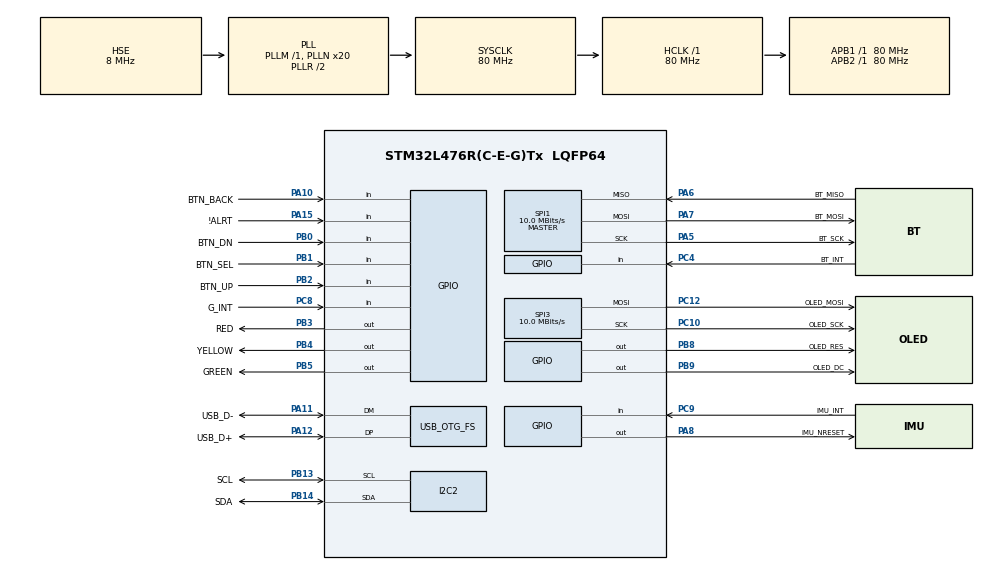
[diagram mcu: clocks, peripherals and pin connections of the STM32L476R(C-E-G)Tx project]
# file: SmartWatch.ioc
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Dma.Request0=SPI3_TX
Dma.Request1=SPI1_TX
Dma.Request2=SPI1_RX
Dma.SPI1_RX.2.Direction=DMA_PERIPH_TO_MEMORY
Dma.SPI1_RX.2.Instance=DMA1_Channel2
Dma.SPI1_RX.2.MemDataAlignment=DMA_MDATAALIGN_BYTE
Dma.SPI1_RX.2.MemInc=DMA_MINC_DISABLE
Dma.SPI1_RX.2.Mode=DMA_NORMAL
Dma.SPI1_RX.2.NoTestForDmaSupport=false
Dma.SPI1_RX.2.PeriphDataAlignment=DMA_PDATAALIGN_BYTE
Dma.SPI1_RX.2.PeriphInc=DMA_PINC_DISABLE
Dma.SPI1_RX.2.Priority=DMA_PRIORITY_LOW
Dma.SPI1_RX.2.Request=DMA_REQUEST_1
Dma.SPI1_TX.1.Direction=DMA_MEMORY_TO_PERIPH
Dma.SPI1_TX.1.Instance=DMA1_Channel3
Dma.SPI1_TX.1.MemDataAlignment=DMA_MDATAALIGN_BYTE
Dma.SPI1_TX.1.MemInc=DMA_MINC_DISABLE
Dma.SPI1_TX.1.Mode=DMA_NORMAL
Dma.SPI1_TX.1.NoTestForDmaSupport=false
Dma.SPI1_TX.1.PeriphDataAlignment=DMA_PDATAALIGN_BYTE
Dma.SPI1_TX.1.PeriphInc=DMA_PINC_DISABLE
Dma.SPI1_TX.1.Priority=DMA_PRIORITY_LOW
Dma.SPI1_TX.1.Request=DMA_REQUEST_1
Dma.SPI3_TX.0.Direction=DMA_MEMORY_TO_PERIPH
Dma.SPI3_TX.0.Instance=DMA2_Channel2
Dma.SPI3_TX.0.MemDataAlignment=DMA_MDATAALIGN_BYTE
Dma.SPI3_TX.0.MemInc=DMA_MINC_DISABLE
Dma.SPI3_TX.0.Mode=DMA_NORMAL
Dma.SPI3_TX.0.NoTestForDmaSupport=false
Dma.SPI3_TX.0.PeriphDataAlignment=DMA_PDATAALIGN_BYTE
Dma.SPI3_TX.0.PeriphInc=DMA_PINC_DISABLE
Dma.SPI3_TX.0.Priority=DMA_PRIORITY_LOW
Dma.SPI3_TX.0.Request=DMA_REQUEST_3
Mcu.Family=STM32L4
Mcu.Name=STM32L476R(C-E-G)Tx
Mcu.Package=LQFP64
NVIC.DMA1_Channel2_IRQn=true\:0\:0\:false
NVIC.DMA1_Channel3_IRQn=true\:0\:0\:false
NVIC.DMA2_Channel2_IRQn=true\:0\:0\:false
NVIC.PriorityGroup=NVIC_PRIORITYGROUP_4
PA10.GPIO_Label=BTN_BACK
PA10.Signal=GPIO_Input
PA11.GPIO_Label=USB_D-
PA11.Mode=Device_Only
PA11.Signal=USB_OTG_FS_DM
PA12.GPIO_Label=USB_D+
PA12.Mode=Device_Only
PA12.Signal=USB_OTG_FS_DP
PA13.GPIO_Label=SWDIO
PA13.Mode=Serial-Wire
PA13.Signal=SYS_JTMS-SWDIO
PA14.GPIO_Label=SWCLK
PA14.Mode=Serial-Wire
PA14.Signal=SYS_JTCK-SWCLK
PA15.GPIO_Label=\!ALRT
PA15.Signal=GPIO_Input
PA5.GPIO_Label=BT_SCK
PA5.Mode=Full_Duplex_Master
PA5.Signal=SPI1_SCK
PA6.GPIO_Label=BT_MISO
PA6.Mode=Full_Duplex_Master
PA6.Signal=SPI1_MISO
PA7.GPIO_Label=BT_MOSI
PA7.Mode=Full_Duplex_Master
PA7.Signal=SPI1_MOSI
PA8.GPIO_Label=IMU_NRESET
PA8.Signal=GPIO_Output
PB0.GPIO_Label=BTN_DN
PB0.Signal=GPIO_Input
PB1.GPIO_Label=BTN_SEL
PB1.Signal=GPIO_Input
PB13.GPIO_Label=SCL
PB13.Mode=I2C
PB13.Signal=I2C2_SCL
PB14.GPIO_Label=SDA
PB14.Mode=I2C
PB14.Signal=I2C2_SDA
PB2.GPIO_Label=BTN_UP
PB2.Signal=GPIO_Input
PB3.GPIO_Label=RED
PB3.GPIO_PuPd=GPIO_PULLDOWN
PB3.Signal=GPIO_Output
PB4.GPIO_Label=YELLOW
PB4.GPIO_ModeDefaultOutputPP=GPIO_MODE_OUTPUT_PP
PB4.GPIO_PuPd=GPIO_PULLDOWN
PB4.Signal=GPIO_Output
PB5.GPIO_Label=GREEN
PB5.GPIO_PuPd=GPIO_PULLDOWN
PB5.Signal=GPIO_Output
PB8.GPIO_Label=OLED_RES
PB8.GPIO_ModeDefaultOutputPP=GPIO_MODE_OUTPUT_PP
PB8.GPIO_PuPd=GPIO_NOPULL
PB8.Signal=GPIO_Output
PB9.GPIO_Label=OLED_DC
PB9.Signal=GPIO_Output
PC10.GPIO_Label=OLED_SCK
PC10.Mode=TX_Only_Simplex_Unidirect_Master
PC10.Signal=SPI3_SCK
PC12.GPIO_Label=OLED_MOSI
PC12.Mode=TX_Only_Simplex_Unidirect_Master
PC12.Signal=SPI3_MOSI
PC14/OSC32_IN.GPIO_Label=OSC32_IN
PC14/OSC32_IN.Mode=LSE-External-Oscillator
PC14/OSC32_IN.Signal=RCC_OSC32_IN
PC15/OSC32_OUT.Mode=LSE-External-Oscillator
PC15/OSC32_OUT.Signal=RCC_OSC32_OUT
PC4.GPIO_Label=BT_INT
PC4.Signal=GPIO_Input
PC8.GPIO_Label=G_INT
PC8.Signal=GPIO_Input
PC9.GPIO_Label=IMU_INT
PC9.Signal=GPIO_Input
PH0/OSC_IN.GPIO_Label=OSC_IN
PH0/OSC_IN.Mode=HSE-External-Oscillator
PH0/OSC_IN.Signal=RCC_OSC_IN
PH1/OSC_OUT.Mode=HSE-External-Oscillator
PH1/OSC_OUT.Signal=RCC_OSC_OUT
ProjectManager.TargetToolchain=SW4STM32
RCC.ADCFreq_Value=48000000
RCC.AHBFreq_Value=80000000
RCC.APB1Freq_Value=80000000
RCC.APB1TimFreq_Value=80000000
RCC.APB2Freq_Value=80000000
RCC.APB2TimFreq_Value=80000000
RCC.CortexFreq_Value=80000000
RCC.HCLKFreq_Value=80000000
RCC.HSE_VALUE=8000000
RCC.HSI_VALUE=16000000
RCC.MSI_VALUE=4000000
RCC.PLLN=20
RCC.PLLSAI1N=12
RCC.PLLSourceVirtual=RCC_PLLSOURCE_HSE
RCC.PREFETCH_ENABLE=1
RCC.RTCClockSelection=RCC_RTCCLKSOURCE_LSE
RCC.SYSCLKFreq_VALUE=80000000
RCC.SYSCLKSource=RCC_SYSCLKSOURCE_PLLCLK
RCC.USBFreq_Value=48000000
RCC.VCOOutputFreq_Value=160000000
SPI1.BaudRatePrescaler=SPI_BAUDRATEPRESCALER_8
SPI1.CalculateBaudRate=10.0 MBits/s
SPI1.Mode=SPI_MODE_MASTER
SPI3.BaudRatePrescaler=SPI_BAUDRATEPRESCALER_8
SPI3.CalculateBaudRate=10.0 MBits/s
SPI3.Mode=SPI_MODE_MASTER
USB_OTG_FS.VirtualMode=Device_Only
VP_RTC_VS_RTC_Alarm_A_Intern.Mode=Alarm A
board=SmartWatch

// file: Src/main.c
/**
  ******************************************************************************
  * File Name          : main.c
  * Description        : Main program body
  ******************************************************************************
  *
  * COPYRIGHT(c) 2015 STMicroelectronics
  *
  * Redistribution and use in source and binary forms, with or without modification,
  * are permitted provided that the following conditions are met:
  *   1. Redistributions of source code must retain the above copyright notice,
  *      this list of conditions and the following disclaimer.
  *   2. Redistributions in binary form must reproduce the above copyright notice,
  *      this list of conditions and the following disclaimer in the documentation
  *      and/or other materials provided with the distribution.
  *   3. Neither the name of STMicroelectronics nor the names of its contributors
  *      may be used to endorse or promote products derived from this software
  *      without specific prior written permission.
  *
  * THIS SOFTWARE IS PROVIDED BY THE COPYRIGHT HOLDERS AND CONTRIBUTORS "AS IS"
  * AND ANY EXPRESS OR IMPLIED WARRANTIES, INCLUDING, BUT NOT LIMITED TO, THE
  * IMPLIED WARRANTIES OF MERCHANTABILITY AND FITNESS FOR A PARTICULAR PURPOSE ARE
  * DISCLAIMED. IN NO EVENT SHALL THE COPYRIGHT HOLDER OR CONTRIBUTORS BE LIABLE
  * FOR ANY DIRECT, INDIRECT, INCIDENTAL, SPECIAL, EXEMPLARY, OR CONSEQUENTIAL
  * DAMAGES (INCLUDING, BUT NOT LIMITED TO, PROCUREMENT OF SUBSTITUTE GOODS OR
  * SERVICES; LOSS OF USE, DATA, OR PROFITS; OR BUSINESS INTERRUPTION) HOWEVER
  * CAUSED AND ON ANY THEORY OF LIABILITY, WHETHER IN CONTRACT, STRICT LIABILITY,
  * OR TORT (INCLUDING NEGLIGENCE OR OTHERWISE) ARISING IN ANY WAY OUT OF THE USE
  * OF THIS SOFTWARE, EVEN IF ADVISED OF THE POSSIBILITY OF SUCH DAMAGE.
  *
  ******************************************************************************
  */
#include "stm32l4xx_hal.h"
#include "dma.h"
#include "i2c.h"
#include "rtc.h"
#include "spi.h"
#include "usb_otg.h"
#include "gpio.h"

/* USER CODE BEGIN Includes */
#include "SSD1306.h" //SSD1306 uses SPI3
/* USER CODE END Includes */

/* USER CODE BEGIN PV */
/* Private variables ---------------------------------------------------------*/

/* USER CODE END PV */

void SystemClock_Config(void);

/* USER CODE BEGIN PFP */
/* Private function prototypes -----------------------------------------------*/

/* USER CODE END PFP */

int main(void)
{

  /* MCU Configuration----------------------------------------------------------*/

  /* Reset of all peripherals, Initializes the Flash interface and the Systick. */
  HAL_Init();

  /* Configure the system clock */
  SystemClock_Config();

  /* Initialize all configured peripherals */
  MX_GPIO_Init();
  MX_DMA_Init();
  MX_I2C2_Init();
  MX_RTC_Init();
  MX_SPI1_Init();
  MX_SPI3_Init();
  MX_USB_OTG_FS_PCD_Init();
  //HAL_SPI_MspInit(&hspi3);

  /* USER CODE BEGIN 2 */

  //begin();
  //setWrap(false);
  //fillRect(0,0,128,20,ColorHSV(1200,255,255));

  // USART_TypeDef USB_UART;
  // HAL_UART_MspInit(&USB_UART);
  // HAL_UART_Init(&USB_UART);

  /* USER CODE END 2 */

  /* Infinite loop */
  char test[5]= "test";
  /* USER CODE BEGIN WHILE */
  while (1)
  {
 //   fillRect(0,0,128,128,ColorHSV(1200,255,255));
    HAL_GPIO_WritePin(RED_GPIO_Port, RED_Pin, GPIO_PIN_SET);
    HAL_Delay(500);
    HAL_GPIO_WritePin(RED_GPIO_Port, RED_Pin, GPIO_PIN_RESET);
    HAL_Delay(500);

  }
  /* USER CODE END 3 */

}

/** System Clock Configuration
*/
void SystemClock_Config(void)
{

  RCC_OscInitTypeDef RCC_OscInitStruct;
  RCC_ClkInitTypeDef RCC_ClkInitStruct;
  RCC_PeriphCLKInitTypeDef PeriphClkInit;

  RCC_OscInitStruct.OscillatorType = RCC_OSCILLATORTYPE_HSE|RCC_OSCILLATORTYPE_LSE;
  RCC_OscInitStruct.HSEState = RCC_HSE_ON;
  RCC_OscInitStruct.LSEState = RCC_LSE_ON;
  RCC_OscInitStruct.PLL.PLLState = RCC_PLL_ON;
  RCC_OscInitStruct.PLL.PLLSource = RCC_PLLSOURCE_HSE;
  RCC_OscInitStruct.PLL.PLLM = 1;
  RCC_OscInitStruct.PLL.PLLN = 20;
  RCC_OscInitStruct.PLL.PLLP = RCC_PLLP_DIV7;
  RCC_OscInitStruct.PLL.PLLQ = RCC_PLLQ_DIV2;
  RCC_OscInitStruct.PLL.PLLR = RCC_PLLR_DIV2;
  HAL_RCC_OscConfig(&RCC_OscInitStruct);

  RCC_ClkInitStruct.ClockType = RCC_CLOCKTYPE_HCLK|RCC_CLOCKTYPE_SYSCLK
                              |RCC_CLOCKTYPE_PCLK1|RCC_CLOCKTYPE_PCLK2;
  RCC_ClkInitStruct.SYSCLKSource = RCC_SYSCLKSOURCE_PLLCLK;
  RCC_ClkInitStruct.AHBCLKDivider = RCC_SYSCLK_DIV1;
  RCC_ClkInitStruct.APB1CLKDivider = RCC_HCLK_DIV1;
  RCC_ClkInitStruct.APB2CLKDivider = RCC_HCLK_DIV1;
  HAL_RCC_ClockConfig(&RCC_ClkInitStruct, FLASH_LATENCY_4);

  PeriphClkInit.PeriphClockSelection = RCC_PERIPHCLK_RTC|RCC_PERIPHCLK_I2C2
                              |RCC_PERIPHCLK_USB;
  PeriphClkInit.I2c2ClockSelection = RCC_I2C2CLKSOURCE_PCLK1;
  PeriphClkInit.RTCClockSelection = RCC_RTCCLKSOURCE_LSE;
  PeriphClkInit.UsbClockSelection = RCC_USBCLKSOURCE_PLLSAI1;
  PeriphClkInit.PLLSAI1.PLLSAI1N = 12;
  PeriphClkInit.PLLSAI1.PLLSAI1P = RCC_PLLP_DIV7;
  PeriphClkInit.PLLSAI1.PLLSAI1Q = RCC_PLLQ_DIV2;
  PeriphClkInit.PLLSAI1.PLLSAI1R = RCC_PLLR_DIV2;
  PeriphClkInit.PLLSAI1.PLLSAI1ClockOut = RCC_PLLSAI1_48M2CLK;
  HAL_RCCEx_PeriphCLKConfig(&PeriphClkInit);

  __PWR_CLK_ENABLE();

  HAL_PWREx_ControlVoltageScaling(PWR_REGULATOR_VOLTAGE_SCALE1);

  HAL_SYSTICK_Config(HAL_RCC_GetHCLKFreq()/1000);

  HAL_SYSTICK_CLKSourceConfig(SYSTICK_CLKSOURCE_HCLK);

  /* SysTick_IRQn interrupt configuration */
  HAL_NVIC_SetPriority(SysTick_IRQn, 0, 0);
}

/************************ (C) COPYRIGHT STMicroelectronics *****END OF FILE****/
